# ESP32S31_RADIO register map
Vendor: Espressif; Series: ESP32-S31; File version: 3.52
Registers are 32-bit, read-write, no defined reset value unless marked. A register's access mark holds for its fields unless they carry their own. Offsets are from the block's base; [hi:lo] are bit positions; {n}, {i} and the like mark numbered series.

## WIFI_MAC_HE_TB_STATISTICS — Hardware counters read by the complete hal_he_get_rx_trigger_cnt, hal_he_get_tb_times_cnt and hal_he_get_tb_qosnull_cnt leaves. These counters distinguish Trigger reception from actual trigger-based transmission and appended QoS Null responses. An ordinary controlled HE SU AP produced no Trigger frames, so all three remained zero during sustained HE DCM A-MPDU traffic.
Base 0x201043A0
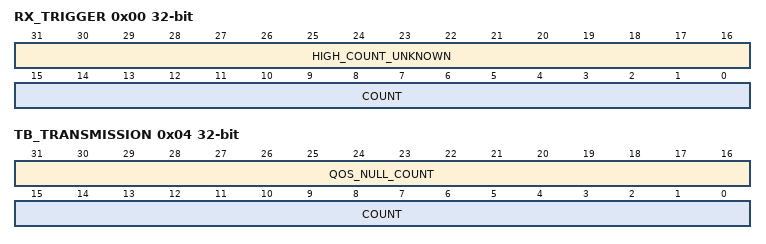
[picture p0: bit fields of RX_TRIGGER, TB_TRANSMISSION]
0x00 RX_TRIGGER ro — Complete hal_he_get_rx_trigger_cnt returns the low sixteen bits.
  [31:16] HIGH_COUNT_UNKNOWN, [15:0] COUNT
0x04 TB_TRANSMISSION ro — Complete hal_he_get_tb_times_cnt returns the low sixteen bits; complete hal_he_get_tb_qosnull_cnt returns the high sixteen bits.
  [31:16] QOS_NULL_COUNT, [15:0] COUNT

## WIFI_MAC_HE_TB_DIAGNOSTICS — Four read-only hardware result words decoded by complete dbg_read_axtb_diag and its four complete getter leaves. The names come from the pinned blob's own format strings; no field meaning is inferred from reset images. All four words remained zero when the controlled AP sent no Trigger frames.
Base 0x201044F4
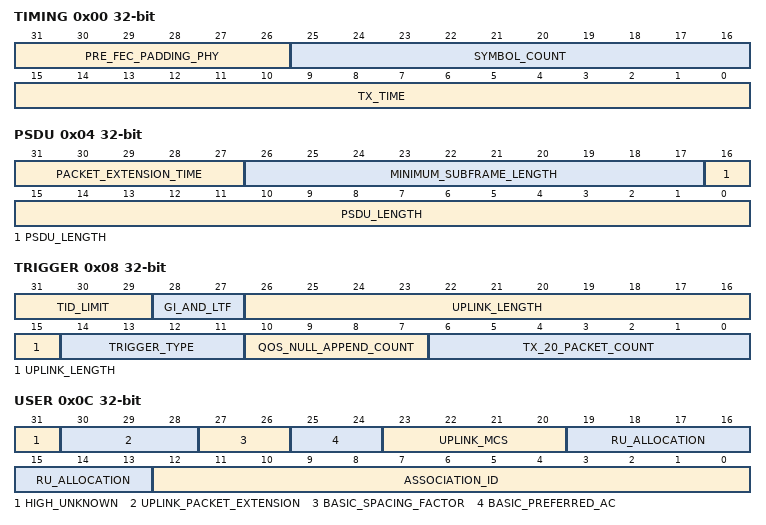
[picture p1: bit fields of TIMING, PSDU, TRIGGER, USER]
0x00 TIMING ro — WDEVAXTBDIAG0.
  [31:26] PRE_FEC_PADDING_PHY, [25:16] SYMBOL_COUNT, [15:0] TX_TIME
0x04 PSDU ro — WDEVAXTBDIAG1.
  [31:27] PACKET_EXTENSION_TIME, [26:17] MINIMUM_SUBFRAME_LENGTH, [16:0] PSDU_LENGTH
0x08 TRIGGER ro — WDEVAXTBDIAG2.
  [31:29] TID_LIMIT, [28:27] GI_AND_LTF, [26:15] UPLINK_LENGTH, [14:11] TRIGGER_TYPE, [10:7] QOS_NULL_APPEND_COUNT, [6:0] TX_20_PACKET_COUNT
0x0C USER ro — WDEVAXTBDIAG3.
  [31] HIGH_UNKNOWN, [30:28] UPLINK_PACKET_EXTENSION, [27:26] BASIC_SPACING_FACTOR, [25:24] BASIC_PREFERRED_AC, [23:20] UPLINK_MCS, [19:13] RU_ALLOCATION, [12:0] ASSOCIATION_ID

## WIFI_MAC_HE_MU_EDCA_TIMER — Four MU-EDCA timer words decoded by complete dbg_read_muedca_timer. Durations are reported by the blob in eight-TU units. Complete blob and ROM mac_tx_set_tb set ENABLE in the timer selected by the logical TX queue before publishing the Trigger queue configuration. After open HE association and TID0 AddBA, all four ordinary-SU baseline words had ENABLE=0, TIMER/CURRENT/AIFS=0 and REACHED=1; that pre-port baseline AP emitted no Trigger frame.
Base 0x20104DBC
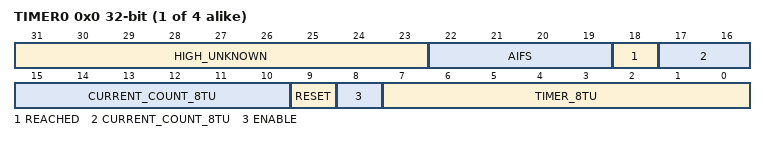
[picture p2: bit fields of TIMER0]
{0x0+4i} TIMER{i} (i=0..3) — WDEVMUEDCA_TIMER[0-3].
  [31:23] HIGH_UNKNOWN, [22:19] AIFS, [18] REACHED, [17:10] CURRENT_COUNT_8TU, [9] RESET, [8] ENABLE, [7:0] TIMER_8TU

## WIFI_MAC_HE_TRIGGER_RX_DIAGNOSTICS — Ten hardware diagnostic words decoded by complete dbg_read_ax_diag. The blob explicitly warns that these words are not latched and can be updated by a following RX frame; consume them only as best-effort diagnostics adjacent to a known Trigger reception.
Base 0x20104508
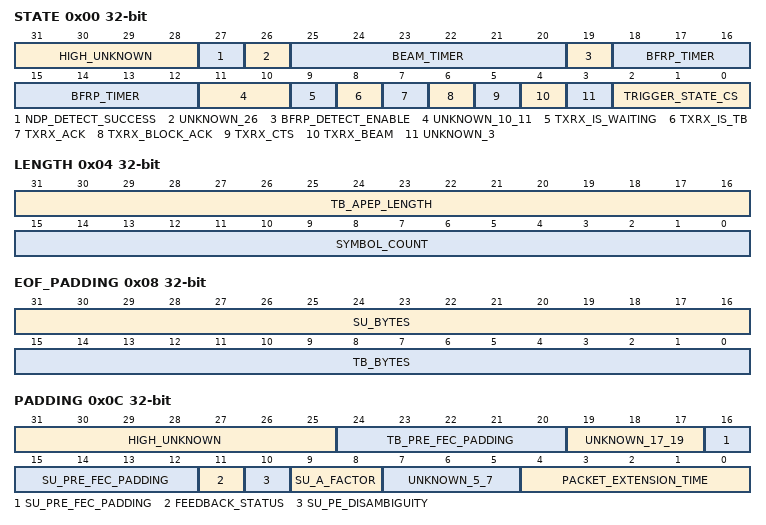
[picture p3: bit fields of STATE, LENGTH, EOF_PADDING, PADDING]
0x00 STATE ro — WDEVAXDIAG0.
  [31:28] HIGH_UNKNOWN, [27] NDP_DETECT_SUCCESS, [26] UNKNOWN_26, [25:20] BEAM_TIMER, [19] BFRP_DETECT_ENABLE, [18:12] BFRP_TIMER, [11:10] UNKNOWN_10_11, [9] TXRX_IS_WAITING, [8] TXRX_IS_TB, [7] TXRX_ACK, [6] TXRX_BLOCK_ACK, [5] TXRX_CTS, [4] TXRX_BEAM, [3] UNKNOWN_3, [2:0] TRIGGER_STATE_CS
0x04 LENGTH ro — WDEVAXDIAG1.
  [31:16] TB_APEP_LENGTH, [15:0] SYMBOL_COUNT
0x08 EOF_PADDING ro — WDEVAXDIAG2. Padding bytes exclude the final subframe padding bytes.
  [31:16] SU_BYTES, [15:0] TB_BYTES
0x0C PADDING ro — WDEVAXDIAG3.
  [31:25] HIGH_UNKNOWN, [24:20] TB_PRE_FEC_PADDING, [19:17] UNKNOWN_17_19, [16:12] SU_PRE_FEC_PADDING, [11] FEEDBACK_STATUS, [10] SU_PE_DISAMBIGUITY, [9:8] SU_A_FACTOR, [7:5] UNKNOWN_5_7, [4:0] PACKET_EXTENSION_TIME
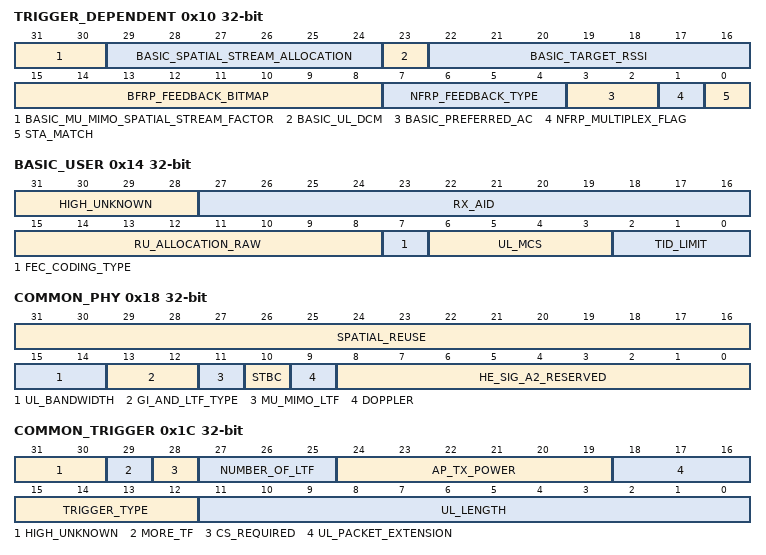
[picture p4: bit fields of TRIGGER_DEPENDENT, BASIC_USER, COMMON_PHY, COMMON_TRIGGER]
0x10 TRIGGER_DEPENDENT ro — WDEVAXDIAG4.
  [31:30] BASIC_MU_MIMO_SPATIAL_STREAM_FACTOR, [29:24] BASIC_SPATIAL_STREAM_ALLOCATION, [23] BASIC_UL_DCM, [22:16] BASIC_TARGET_RSSI, [15:8] BFRP_FEEDBACK_BITMAP, [7:4] NFRP_FEEDBACK_TYPE, [3:2] BASIC_PREFERRED_AC, [1] NFRP_MULTIPLEX_FLAG, [0] STA_MATCH
0x14 BASIC_USER ro — WDEVAXDIAG5.
  [31:28] HIGH_UNKNOWN, [27:16] RX_AID, [15:8] RU_ALLOCATION_RAW, [7] FEC_CODING_TYPE, [6:3] UL_MCS, [2:0] TID_LIMIT
0x18 COMMON_PHY ro — WDEVAXDIAG6.
  [31:16] SPATIAL_REUSE, [15:14] UL_BANDWIDTH, [13:12] GI_AND_LTF_TYPE, [11] MU_MIMO_LTF, [10] STBC, [9] DOPPLER, [8:0] HE_SIG_A2_RESERVED
0x1C COMMON_TRIGGER ro — WDEVAXDIAG7.
  [31:30] HIGH_UNKNOWN, [29] MORE_TF, [28] CS_REQUIRED, [27:25] NUMBER_OF_LTF, [24:19] AP_TX_POWER, [18:16] UL_PACKET_EXTENSION, [15:12] TRIGGER_TYPE, [11:0] UL_LENGTH
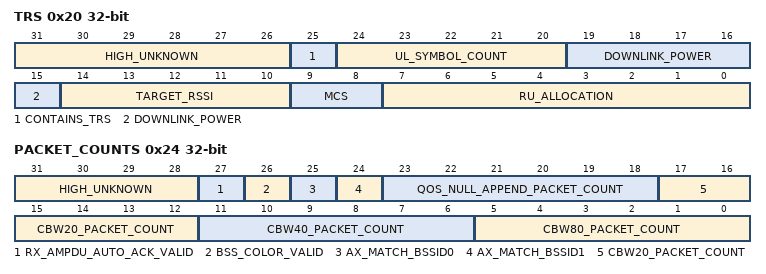
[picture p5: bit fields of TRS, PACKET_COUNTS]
0x20 TRS ro — WDEVAXDIAG8.
  [31:26] HIGH_UNKNOWN, [25] CONTAINS_TRS, [24:20] UL_SYMBOL_COUNT, [19:15] DOWNLINK_POWER, [14:10] TARGET_RSSI, [9:8] MCS, [7:0] RU_ALLOCATION
0x24 PACKET_COUNTS ro — WDEVAXDIAG9.
  [31:28] HIGH_UNKNOWN, [27] RX_AMPDU_AUTO_ACK_VALID, [26] BSS_COLOR_VALID, [25] AX_MATCH_BSSID0, [24] AX_MATCH_BSSID1, [23:18] QOS_NULL_APPEND_PACKET_COUNT, [17:12] CBW20_PACKET_COUNT, [11:6] CBW40_PACKET_COUNT, [5:0] CBW80_PACKET_COUNT
